# GD32W515 register map
File version: 1.0
CPU: CM33 r0p4, little endian, MPU, FPU, 4 interrupt priority bits
Registers are 32-bit, read-write, reset 0x0 unless marked. A register's access mark holds for its fields unless they carry their own. Offsets are from the block's base; [hi:lo] are bit positions; {n}, {i} and the like mark numbered series.

## SYSCFG — System configuration controller
Base 0x40013800
Same registers: SEC_SYSCFG 0x50013800
0x00 CFG0 — Configuration register 0
  [1:0] BOOT_MODE
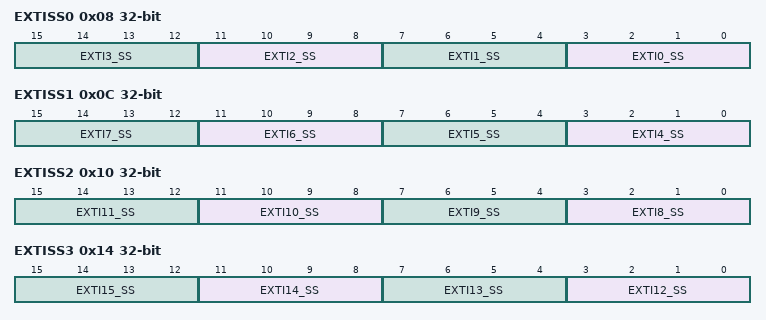
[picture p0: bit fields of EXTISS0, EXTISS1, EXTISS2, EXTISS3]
0x08 EXTISS0 — EXTI sources selection register 0
  [4n+3:4n] EXTI{n}_SS (n=0..3) — EXTI {n} sources selection
0x0C EXTISS1 — EXTI sources selection register 1
  [4n-13:4n-16] EXTI{n}_SS (n=4..7) — EXTI {n} sources selection
0x10 EXTISS2 — EXTI sources selection register 2
  [4n-29:4n-32] EXTI{n}_SS (n=8..11) — EXTI {n} sources selection
0x14 EXTISS3 — EXTI sources selection register 3
  [4n-45:4n-48] EXTI{n}_SS (n=12..15) — EXTI {n} sources selection
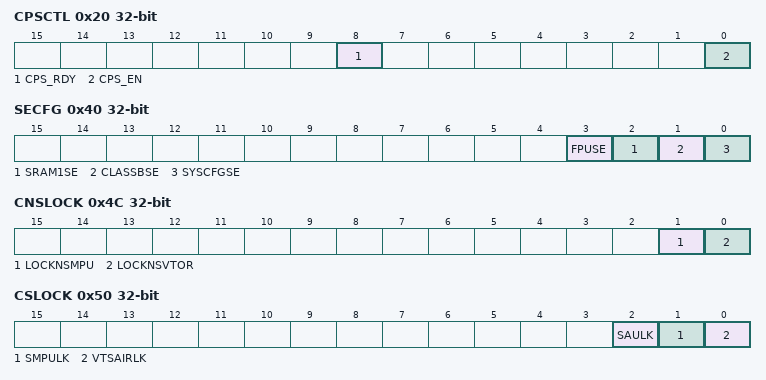
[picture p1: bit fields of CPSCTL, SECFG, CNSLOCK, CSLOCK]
0x20 CPSCTL access per field — I/O compensation control register
  [8] CPS_RDY ro — I/O compensation cell is ready or not
  [0] CPS_EN rw — I/O compensation cell enable
0x40 SECFG — SYSCFG secure configuration register
  [3] FPUSE — FPU security
  [2] SRAM1SE — SRAM1 security
  [1] CLASSBSE — ClassB security
  [0] SYSCFGSE — SYSCFG clock control security
0x48 FPUINTMSK reset 0x1F — FPU interrupt mask register
  [5:0] FPU_IE — Floating point unit interrupts enable bits
0x4C CNSLOCK — SYSCFG CPU non-secure lock register
  [1] LOCKNSMPU — Non-secure MPU registers lock
  [0] LOCKNSVTOR — VTOR_NS register lock
0x50 CSLOCK — SYSCFG CPU secure lock register
  [2] SAULK — SAU registers lock
  [1] SMPULK — Secure MPU registers lock
  [0] VTSAIRLK — VTOR_S register and AIRCR register bits lock
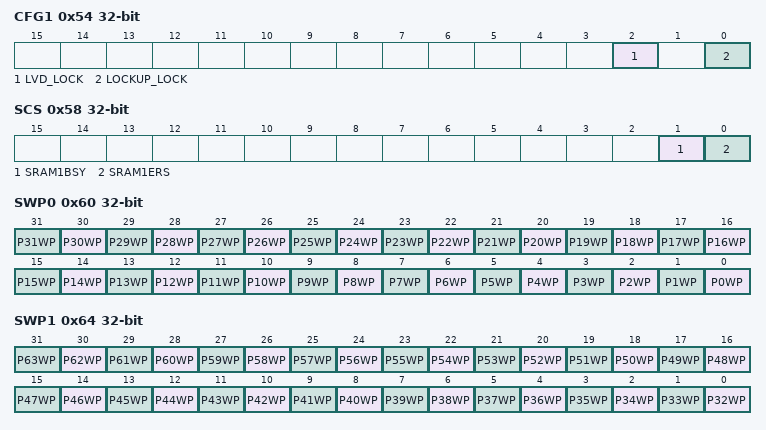
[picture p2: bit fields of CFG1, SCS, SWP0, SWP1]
0x54 CFG1 — SYSCFG configuration register 1
  [2] LVD_LOCK — LVD lock enable bit
  [0] LOCKUP_LOCK — Cortex M33 LOCKUP (hardfault) output enable bit
0x58 SCS access per field — SYSCFG SRAM1 control and status register
  [1] SRAM1BSY ro — SRAM1 busy by erase operation
  [0] SRAM1ERS rw — SRAM1 erase
0x5C SKEY wo — SYSCFG SRAM1 key register
  [7:0] KEY — SRAM1 write protection key for software erase
0x60 SWP0 — SYSCFG SRAM1 write protection register 0
  [n] P{n}WP (n=0..31) — SRAM1 1 Kbyte page {n} write protection
0x64 SWP1 — SYSCFG SRAM1 write protection register 1
  [n-32] P{n}WP (n=32..63) — SRAM1 1 Kbyte page {n} write protection
0x6C RSSCMD — SYSCFG RSS command register
  [7:0] RSSCMD — RSS commands

## TIMER5 — Basic-timers
Base 0x40001000
Same registers: SEC_TIMER5 0x50001000
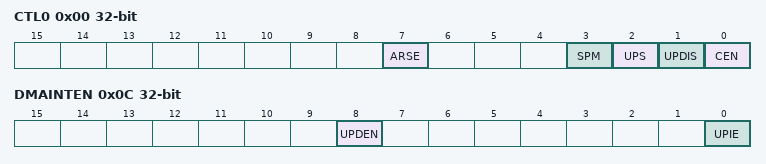
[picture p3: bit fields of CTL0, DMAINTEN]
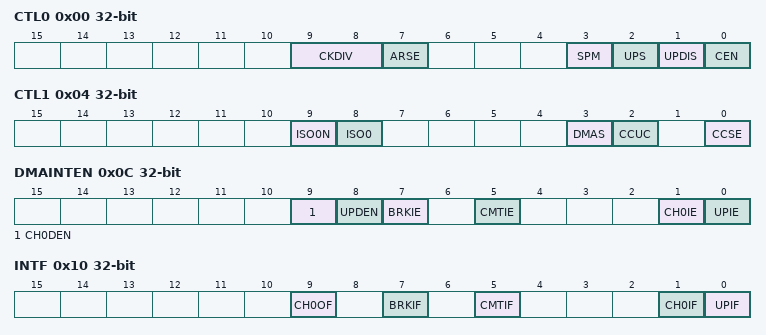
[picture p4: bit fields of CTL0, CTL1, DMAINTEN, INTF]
0x00 CTL0 — control register 0
  [7] ARSE — Auto-reload preload enable
  [3] SPM — One-pulse mode
  [2] UPS — Update request source
  [1] UPDIS — Update disable
  [0] CEN — Counter enable
0x04 CTL1 — control register 1
  [6:4] MMC — Master mode selection
0x0C DMAINTEN — DMA/Interrupt enable register
  [8] UPDEN — Update DMA request enable
  [0] UPIE — Update interrupt enable
0x10 INTF — status register
  [0] UPIF — Update interrupt flag
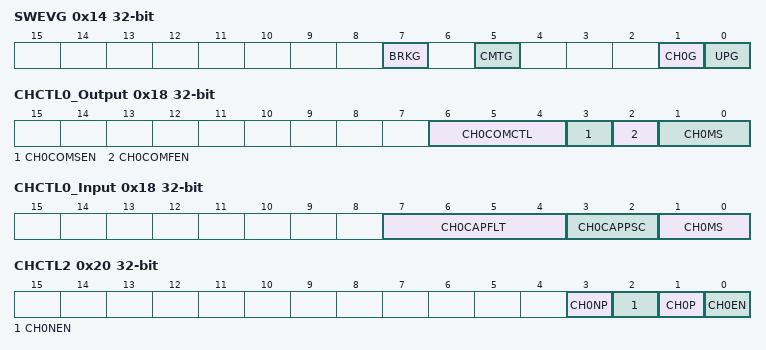
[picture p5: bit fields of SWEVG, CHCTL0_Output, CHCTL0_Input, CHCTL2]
0x14 SWEVG wo — event generation register
  [0] UPG — Update generation
0x24 CNT — counter
  [15:0] CNT — Low counter value
0x28 PSC — prescaler
  [15:0] PSC — Prescaler value
0x2C CAR — auto-reload register
  [15:0] CARL — Low Auto-reload value

## TIMER15 — General-purpose-timers
Base 0x40018000
Same registers: TIMER16 0x40018400, SEC_TIMER15 0x50018000, SEC_TIMER16 0x50018400
0x00 CTL0 — control register 0
  [9:8] CKDIV — Clock division
  [7] ARSE — Auto-reload preload enable
  [3] SPM — One-pulse mode
  [2] UPS — Update request source
  [1] UPDIS — Update disable
  [0] CEN — Counter enable
0x04 CTL1 — control register 1
  [9] ISO0N — Output Idle state 0
  [8] ISO0 — Output Idle state 0
  [3] DMAS — Capture/compare DMA selection
  [2] CCUC — Capture/compare control update selection
  [0] CCSE — Capture/compare preloaded control
0x0C DMAINTEN — DMA/Interrupt enable register
  [9] CH0DEN — Capture/Compare 0 DMA request enable
  [8] UPDEN — Update DMA request enable
  [7] BRKIE — Break interrupt enable
  [5] CMTIE — COM interrupt enable
  [1] CH0IE — Capture/Compare 0 interrupt enable
  [0] UPIE — Update interrupt enable
0x10 INTF — interrupt flag register
  [9] CH0OF — Capture/Compare 0 overcapture flag
  [7] BRKIF — Break interrupt flag
  [5] CMTIF — COM interrupt flag
  [1] CH0IF — Capture/compare 0 interrupt flag
  [0] UPIF — Update interrupt flag
0x14 SWEVG wo — event generation register
  [7] BRKG — Break generation
  [5] CMTG — Capture/Compare control update generation
  [1] CH0G — Capture/compare 0 generation
  [0] UPG — Update generation
0x18 CHCTL0_Output — capture/compare mode register (output mode)
  [6:4] CH0COMCTL — Output Compare 0 mode
  [3] CH0COMSEN — Output Compare 0 preload enable
  [2] CH0COMFEN — Output Compare 0 fast enable
  [1:0] CH0MS — Capture/Compare 0 selection
0x18 CHCTL0_Input (alternate view of CHCTL0_Output) — capture/compare mode register 0 (input mode)
  [7:4] CH0CAPFLT — Input capture 0 filter
  [3:2] CH0CAPPSC — Input capture 0 prescaler
  [1:0] CH0MS — Capture/Compare 0 selection
0x20 CHCTL2 — capture/compare enable register
  [3] CH0NP — Capture/Compare 0 output Polarity
  [2] CH0NEN — Capture/Compare 0 complementary output enable
  [1] CH0P — Capture/Compare 0 output Polarity
  [0] CH0EN — Capture/Compare 0 output enable
0x24 CNT — counter
  [15:0] CNT — counter value
0x28 PSC — prescaler
  [15:0] PSC — Prescaler value
0x2C CAR — auto-reload register
  [15:0] CARL — Auto-reload value
0x30 CREP — repetition counter register
  [7:0] CREP — Repetition counter value
0x34 CH0CV — capture/compare register 0
  [15:0] CH0VAL — Capture/Compare 0 value
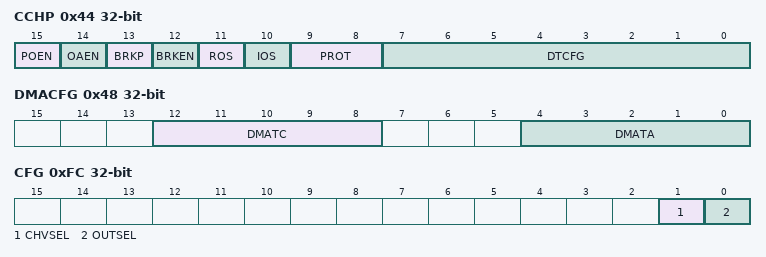
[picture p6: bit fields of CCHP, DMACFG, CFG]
0x44 CCHP — break and dead-time register
  [15] POEN — Main output enable
  [14] OAEN — Automatic output enable
  [13] BRKP — Break polarity
  [12] BRKEN — Break enable
  [11] ROS — Off-state selection for Run mode
  [10] IOS — Off-state selection for Idle mode
  [9:8] PROT — complementary register protect control
  [7:0] DTCFG — Dead-time generator setup
0x48 DMACFG — DMA configuration register
  [12:8] DMATC — DMA transfer count
  [4:0] DMATA — DMA transfer access start address
0x4C DMATB — DMA transfer buffer register
  [15:0] DMATB — DMA register for burst accesses
0xFC CFG — configuration register
  [1] CHVSEL — Write CHxVAL register selection
  [0] OUTSEL — The output value selection
